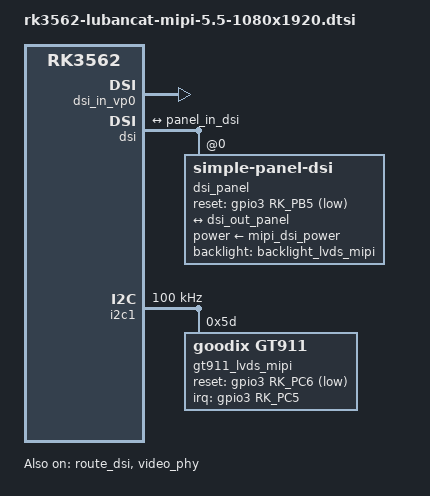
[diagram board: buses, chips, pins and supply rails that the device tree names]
// SPDX-License-Identifier: (GPL-2.0+ OR MIT)
/*
 * Copyright (c) 2024 Rockchip Electronics Co., Ltd.
 *
 */

&route_dsi {
	status = "okay";
	connect = <&vp0_out_dsi>;
};

&video_phy {
	status = "okay";
};

&dsi_in_vp0 {
	status = "okay";
};

&dsi {
	status = "okay";
	#address-cells = <1>;
	#size-cells = <0>;

	dsi_panel: panel@0 {
		status = "okay";
		compatible = "simple-panel-dsi";
		reg = <0>;
		backlight = <&backlight_lvds_mipi>;
		power-supply=<&mipi_dsi_power>;
		reset-gpios = <&gpio3 RK_PB5 GPIO_ACTIVE_LOW>;
		pinctrl-names = "default";
		pinctrl-0 = <&lcd_rst_gpio>;

		enable-delay-ms = <35>;
		prepare-delay-ms = <6>;
		reset-delay-ms = <10>;
		init-delay-ms = <50>;
		unprepare-delay-ms = <0>;
		disable-delay-ms = <20>;

		size,width = <74>;
		size,height = <133>;

		dsi,flags = <(MIPI_DSI_MODE_VIDEO | MIPI_DSI_MODE_VIDEO_BURST | MIPI_DSI_MODE_LPM)>;
		dsi,format = <MIPI_DSI_FMT_RGB888>;
		dsi,lanes  = <4>;

		panel-init-sequence = [
			39 01 04 B9 83 11 2A
			39 01 05 CF 00 14 00 C0
			15 01 02 CC 08
			39 01 05 C9 04 0A 8C 01
			39 01 09 B1 08 29 29 80 80 4F 4A AA
			39 01 10 B2 00 02 00 70 80 00 08 2A 1A 11 15 00 10 A3 87
			39 01 03 D2 2C 2C
			39 01 1C B4 02 D4 02 D4 02 BA 04 D4 00 00 04 D4 00 FF 00 FF 00 00 0C 12 00 2D 0E 0E 13 00 8E
			39 01 09 C7 00 00 04 E0 33 00 20 40
			39 01 04 B6 7B 7B E3
			39 01 2B D3 C0 00 00 00 00 00 00 05 05 04 04 00 1F 0B 0B 0B 0B 32 10 0A 00 0A 32 16 23 06 23 32 10 06 00 06 00 00 00 00 00 00 00 0A 07 8B
			15 01 02 BD 01
			39 01 04 CB 25 11 00
			15 01 02 BD 00
			39 01 31 D5 18 18 18 18 18 18 18 18 18 18 18 18 18 18 18 18 18 18 18 18 18 18 18 18 40 40 19 19 18 18 20 20 04 04 03 03 02 02 01 01 00 00 31 31 30 30 2F 2F
			39 01 31 D6 18 18 18 18 18 18 18 18 18 18 18 18 18 18 18 18 18 18 18 18 18 18 18 18 40 40 19 19 18 18 20 20 00 00 01 01 02 02 03 03 04 04 31 31 30 30 2F 2F
			39 01 19 D8 AA AA AA BA FF EA AA AA AA BA FF EA AA AA AA BA AA AA AA AA AA BA AA AA
			15 01 02 BD 01
			39 01 19 D8 AA AA AA EA FF FF AA AA AA EA FF FF AA AA AA EA FF FF AA AA AA EA FF FF
			15 01 02 BD 02
			39 01 0D D8 AA AA AA EA FF FF AA AA AA EA FF FF
			15 01 02 BD 03
			39 01 19 D8 AA AA AA BA FF EA AA AA AA BA FF EA AA AA AA EB FF FF AA AA AA EB FF FF
			15 01 02 BD 00
			39 01 18 E7 0F 0F 1E 74 1E 72 00 50 02 02 00 00 02 02 02 05 14 14 32 B9 23 B9 08
			15 01 02 BD 01
			39 01 09 E7 02 00 80 01 80 0E 85 0F
			15 01 02 BD 02
			39 01 1E E7 00 00 08 00 01 00 00 00 00 00 00 00 00 00 00 00 00 00 00 00 00 00 04 00 00 00 00 02 00
			15 01 02 BD 00
			15 01 02 E9 C3
			39 01 03 CB D2 35
			15 01 02 E9 3F
			15 01 02 C1 01
			15 01 02 BD 01
			15 01 02 E9 C8
			15 01 02 D3 81
			15 01 02 E9 3F
			15 01 02 BD 00
			39 01 03 C1 01 00
			15 01 02 BD 01
			39 01 3A C1 FF F9 F4 EE E9 E3 DF D5 D0 CA C4 BF BA B5 B0 AB A6 A2 9D 94 8C 84 7C 75 6D 65 5E 57 50 49 43 3D 36 2F 28 21 1B 15 0E 08 06 05 02 01 00 31 71 CB E7 CA 4C 7F 5C 0B 5B 1B 40
			15 01 02 BD 02
			39 01 3A C1 FF FA F4 EF EA E5 E1 D7 D2 CC C7 C2 BD B9 B4 AF AB A6 A2 99 91 89 82 7B 73 6C 65 5E 58 51 4A 45 3F 38 31 2B 25 1E 19 12 0F 0D 0C 0A 0A 09 A1 B6 C5 21 60 EB 18 2C 32 77 40
			15 01 02 BD 03
			39 01 3A C1 FF FA F6 F1 EC E7 E3 D9 D4 CE C9 C4 BF BB B6 B2 AD A9 A5 9C 94 8C 85 7E 77 71 6A 63 5D 56 50 49 44 3E 38 31 2B 25 1F 18 16 14 13 11 11 30 71 79 D8 51 7B C6 72 A6 13 9A 00
			15 01 02 BD 00
			05 78 01 11
			05 0A 01 29
		];

		panel-exit-sequence = [
			05 78 01 28
			05 00 01 10
		];

		disp_timings0: display-timings {
			native-mode = <&dsi_timing0>;
			dsi_timing0: timing0 {
				clock-frequency = <142000000>;// (1920+4+3+1)*(1080+96+33+12)*60=134800000
				hactive = <1080>;
				hfront-porch = <28>;
				hback-porch = <13>;
				hsync-len = <5>;
				vactive = <1920>;
				vfront-porch = <44>;
				vback-porch = <5>;
				vsync-len = <5>;
				hsync-active = <0>;
				vsync-active = <0>;
				de-active = <0>;
				pixelclk-active = <0>;
			};
		};

 		ports {
 			#address-cells = <1>;
 			#size-cells = <0>;
 			port@0 {
 				reg = <0>;
 				panel_in_dsi: endpoint {
 					remote-endpoint = <&dsi_out_panel>;
 				};
 			};
 		};
	};

	ports {
		#address-cells = <1>;
		#size-cells = <0>;
		port@1 {
			reg = <1>;
			dsi_out_panel: endpoint {
				remote-endpoint = <&panel_in_dsi>;
			};
		};
	};
};

&i2c1 {
	status = "okay";
	pinctrl-names = "default";
	pinctrl-0 = <&i2c1m1_xfer>;
	clock-frequency = <100000>;

	gt911_lvds_mipi: gt911@5d {
		status = "okay";
		compatible = "goodix,gt911";
		reg = <0x5d>;
		interrupt-parent = <&gpio3>;
		interrupts = <RK_PC5 IRQ_TYPE_LEVEL_LOW>;
		reset-gpios = <&gpio3 RK_PC6 GPIO_ACTIVE_LOW>;
		irq-gpios = <&gpio3 RK_PC5 GPIO_ACTIVE_HIGH>;
		touchscreen-inverted-x = <1>;
		touchscreen-inverted-y = <1>;
	};
};
